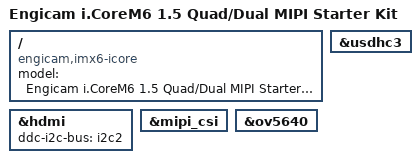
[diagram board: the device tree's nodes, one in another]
// SPDX-License-Identifier: GPL-2.0 OR X11
/*
 * Copyright (C) 2017 Engicam S.r.l.
 * Copyright (C) 2017 Amarula Solutions B.V.
 * Author: Jagan Teki <jagan@amarulasolutions.com>
 */

/dts-v1/;

#include "imx6q.dtsi"
#include "imx6qdl-icore-1.5.dtsi"

/ {
	model = "Engicam i.CoreM6 1.5 Quad/Dual MIPI Starter Kit";
	compatible = "engicam,imx6-icore", "fsl,imx6q";
};

&hdmi {
	ddc-i2c-bus = <&i2c2>;
	status = "okay";
};

&mipi_csi {
	status = "okay";
};

&ov5640 {
	status = "okay";
};

&usdhc3 {
	status = "okay";
};
